# RTS5921 register map
Vendor: Realtek Semiconductor Corp.; Series: RTS5921 Series; File version: 0.01
CPU: ARMV8MBL r0p0, little endian, MPU, no FPU, VTOR, 3 interrupt priority bits
Registers are 32-bit, read-write, reset 0x0 unless marked. A register's access mark holds for its fields unless they carry their own. Offsets are from the block's base; [hi:lo] are bit positions; {n}, {i} and the like mark numbered series.

## UART — UART Controller
Base 0x40100700
0x00 RBR ro — RECEIVE BUFFER REGISTER
0x00 THR (alternate view of RBR) — TRANSMIT HOLDING REGISTER
0x00 DLL (alternate view of RBR) — DIVISOR LATCH LOW REGISTER
0x04 DLH — DIVISOR LATCH HIGH REGISTER
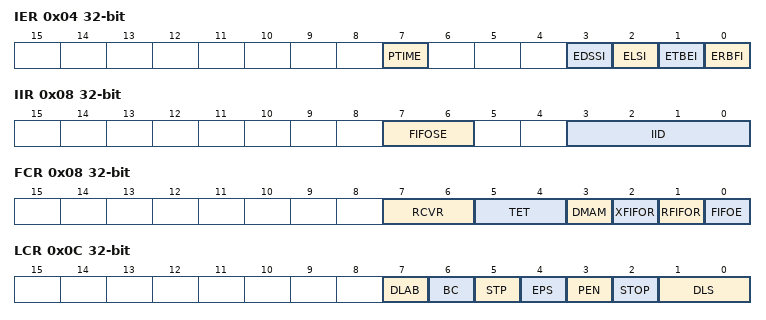
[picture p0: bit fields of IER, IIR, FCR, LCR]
0x04 IER (alternate view of DLH) — INTRRRUPT ENABLE REGISTER
  [7] PTIME — Programmable THRE Interrupt Mode Enable
    0=DISABLE (Disable programmable THRE interrupt mode); 1=ENABLE (Enable programmable THRE interrupt mode)
  [3] EDSSI — Enable Modem Status Interrupt
    0=DISABLE (Disable modem status interrupt); 1=ENABLE (Enable modem status interrupt)
  [2] ELSI — Enable Receiver Line Status Interrupt
    0=DISABLE (Disable receiver line status interrupt); 1=ENABLE (Enable receiver line status interrupt)
  [1] ETBEI — Enable Transmit Holding Register Empty Interrupt
    0=DISABLE (Disable transmit holding register empty interrupt); 1=ENABLE (Enable transmit holding register empty interrupt)
  [0] ERBFI — Enable Received Data Available Interrupt
    0=DISABLE (Disable received data available interrupt); 1=ENABLE (Enable received data available interrupt)
0x08 IIR ro — INTERRUPT IDENTIFICATION
  [7:6] FIFOSE — FIFOs Enabled
    0=DISABLE (FIFOs is disabled); 3=ENABLE (FIFOs is enabled); other=NOT_USED (Reserved values. Do not use.)
  [3:0] IID — Interrupt ID
    0=MODEM (Modem status); 1=HAVE_NO_INT (No interrupt pending); 2=THR_EMPTY; 4=RX_AVL (Received data available); 6=LINE_AVL (Receiver line status); 7=BUSY_DET (Busy detect); 12=CHAR_TO (Character Timeout); other=NOT_USED (Reserved values. Do not use.)
0x08 FCR (alternate view of IIR) — FIFO CONTROL REGISTER
  [7:6] RCVR — Rx Trigger Level
    0=1xCHAR in FIFO; 1=1/4 (1/4 full); 2=1/2 (1/2 full); 3=2 less than full
  [5:4] TET — TX Empty Trigger Level
    0=EMPTY (FIFO Empty); 1=2xCHAR in FIFO; 2=1/4 (1/4 full); 3=1/2 (1/2 full)
  [3] DMAM — DMA Mode
    0=MODE0; 1=MODE1
  [2] XFIFOR — Tx FIFO Reset
    0=NO_EFFECT; 1=RESET
  [1] RFIFOR — Rx FIFO Reset
    0=NO_EFFECT; 1=RESET
  [0] FIFOE — FIFO Enabled
    0=DISABLE (Disable FIFOs); 1=ENABLE (Enable FIFOs)
0x0C LCR — LINE CONTROL REGISTER
  [7] DLAB — Divisor Latch Access Bit
    0=DISABLE (Disable divisor latch access); 1=ENABLE (Enable divisor latch access)
  [6] BC — Break Control Bit
    0=DISABLE (Disable break control); 1=ENABLE (Enable break control)
  [5] STP — Stick Parity
    0=DISABLE (Disable stick parity); 1=ENABLE (Enable stick parity)
  [4] EPS — Even Parity Select
    0=ODD (Odd parity); 1=EVEN (Even parity)
  [3] PEN — Parity Enable
    0=DISABLE (Disable parity); 1=ENABLE (Enable parity)
  [2] STOP — Number of Stop Bits
    0=1_BIT (1 stop bit); 1=1_5_BIT (1.5 stop bits when DLS (LCR[1:0]) is 0, else 2 stop bit)
  [1:0] DLS — Data Length Select
    {v}={v+5}_BIT (Data Length is {v+5}-bit) (v=0..3)
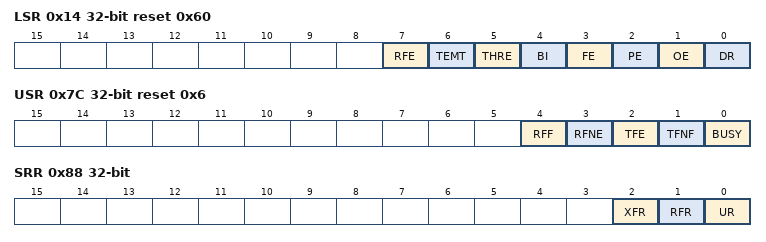
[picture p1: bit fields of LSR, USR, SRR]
0x14 LSR ro reset 0x60 — LINE STATUS REGISTER
  [7] RFE — Receiver FIFO Error
    0=NO_ERR (No receiver FIFO error); 1=ERR (Receiver FIFO error occrred)
  [6] TEMT — Transmitter Empty Bit
    0=NOT_EMPTY (No transmitter empty); 1=EMPTY (Transmitter empty)
  [5] THRE — Transmit Holding Register Empty bit
    0=NOT_EMPTY (Transmit Holding Register is not empty); 1=EMPTY (Transmit Holding Register is empty)
  [4] BI — Break Interrupt bit
    0=NO_ERR (No break interrupt); 1=ERR (Break interrupt occrred)
  [3] FE — Framing Error bit
    0=NO_ERR (No framing error); 1=ERR (framing error occrred)
  [2] PE — Parity Error bit
    0=NO_ERR (No parity error); 1=ERR (Parity error)
  [1] OE — Overrun Error bit
    0=NO_ERR (No oerrun error); 1=ERR (Overrun error)
  [0] DR — Data Ready Bit
    0=NOT_READY (No data ready); 1=READY (Data ready)
0x7C USR ro reset 0x6 — UART Status Register
  [4] RFF — Receive FIFO Full
    0=NOT_FULL (Receive FIFO not full); 1=FULL (Receive FIFO Full)
  [3] RFNE — Receive FIFO Not Empty
    0=EMPTY (Receive FIFO is empty); 1=NOT_EMPTY (Receive FIFO is not empty)
  [2] TFE — Transmit FIFO Empty
    0=NOT_EMPTY (Transmit FIFO is not empty); 1=EMPTY (Transmit FIFO is empty)
  [1] TFNF — Transmit FIFO Not Full
    0=FULL (Transmit FIFO is full); 1=NOT_FULL (Transmit FIFO is not full)
  [0] BUSY — UART Busy
    0=IDLE (UART idle or inactive); 1=BUSY (UART is busy)
0x80 TFL ro — UART TRANSMIT FIFO LEVEL
0x84 RFL ro — UART RECEIVE FIFO LEVEL
0x88 SRR wo — UART SOFTWARE RESET REGISTER
  [all] fields
    0=NO_EFFECT; 1=RESET
  [2] XFR — XMIT FIFO Reset
  [1] RFR — RCVR FIFO Reset
  [0] UR — UART Reset
